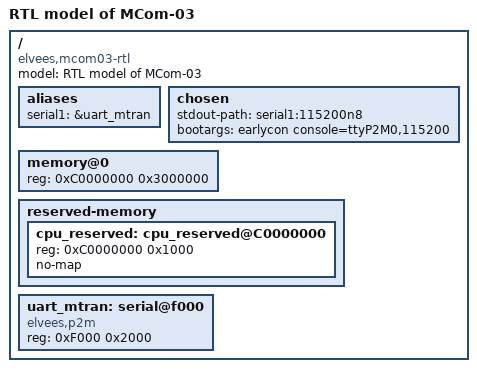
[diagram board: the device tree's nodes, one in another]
// SPDX-License-Identifier: GPL-2.0
/*
 * Copyright 2019 RnD Center "ELVEES", JSC
 *
 * This program is free software; you can redistribute it and/or modify
 * it under the terms of the GNU General Public License as published by
 * the Free Software Foundation; either version 2 of the License, or
 * (at your option) any later version.
 */

/dts-v1/;

#include "mcom03.dtsi"

/ {
	model = "RTL model of MCom-03";
	compatible = "elvees,mcom03-rtl";

	aliases {
		serial1 = &uart_mtran;
	};

	chosen {
		stdout-path = "serial1:115200n8";
		bootargs = "earlycon console=ttyP2M0,115200";
	};

	memory@0 {
		device_type = "memory";
		reg = <0xC0000000 0x3000000>; /* 48 MiB */
	};

	reserved-memory {
		#address-cells = <1>;
		#size-cells = <1>;
		ranges;

		cpu_reserved: cpu_reserved@C0000000 {
			reg = <0xC0000000 0x1000>;
			no-map;
		};
	};

	uart_mtran: serial@f000 {
		compatible = "elvees,p2m";
		reg = <0xF000 0x2000>;
	};
};
